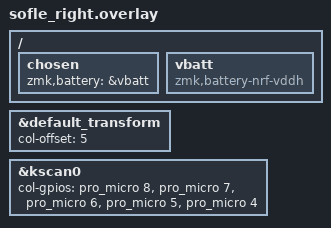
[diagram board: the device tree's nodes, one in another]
#include "sofle.dtsi"
#include <dt-bindings/zmk/pointing.h>

&default_transform {
    col-offset = <5>;
};

&kscan0 {
    col-gpios
        = <&pro_micro 8 GPIO_ACTIVE_HIGH>
        , <&pro_micro 7 GPIO_ACTIVE_HIGH>
        , <&pro_micro 6 GPIO_ACTIVE_HIGH>
        , <&pro_micro 5 GPIO_ACTIVE_HIGH>
        , <&pro_micro 4 GPIO_ACTIVE_HIGH>
        ;
};

/ {
    chosen {
      zmk,battery = &vbatt;
    };

    vbatt: vbatt {
        compatible = "zmk,battery-nrf-vddh";
    };
};
